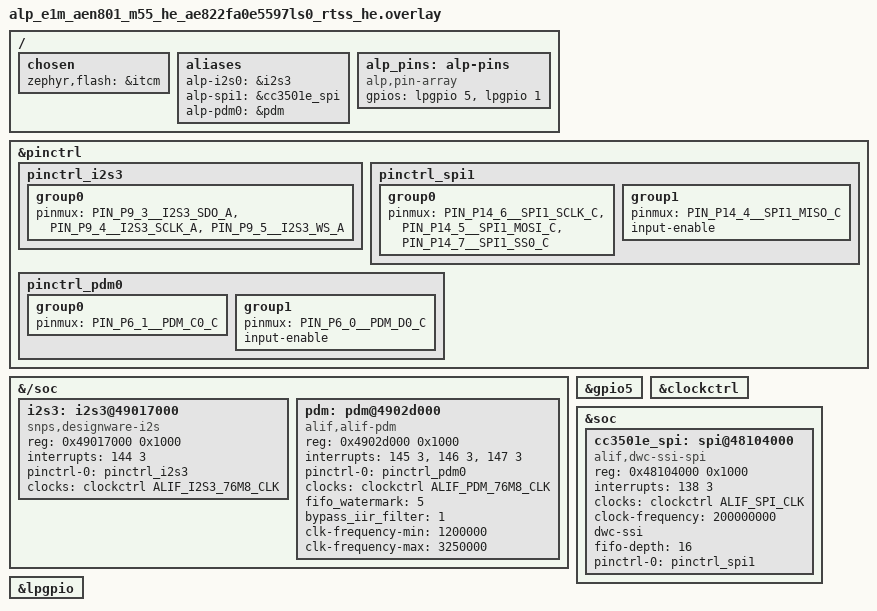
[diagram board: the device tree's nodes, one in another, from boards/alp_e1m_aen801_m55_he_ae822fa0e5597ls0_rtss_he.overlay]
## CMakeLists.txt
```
# SPDX-License-Identifier: Apache-2.0
cmake_minimum_required(VERSION 3.20)

# PROBE_UNDERRUN (#2149 bench verification) needs CONFIG_LOG on -- see
# underrun.conf's own header. OVERLAY_CONFIG has to be set BEFORE
# find_package(Zephyr...) below for Zephyr's own Kconfig merge to pick it
# up; every other PROBE_* mode leaves PROBE_UNDERRUN undefined, so this is a
# no-op for them.
if(DEFINED PROBE_UNDERRUN)
  list(APPEND OVERLAY_CONFIG "${CMAKE_CURRENT_SOURCE_DIR}/underrun.conf")
endif()

find_package(Zephyr REQUIRED HINTS $ENV{ZEPHYR_BASE})
project(aen_i2s_tas2563_probe LANGUAGES C)
target_sources(app PRIVATE src/main.c)

# BENCH-TEST (test/u46-i2s-tas2563-on-reworked-mux), not upstream: the
# CC3501E bridge bring-up helper + this app's two-entry GPIO-proxy route
# table, needed to drive the I2S0 mux SELECT + ENABLE (E1M IO13/IO8) before
# touching i2s3 on the reworked e1m-aen-evk-03 bench board -- see the board
# overlay and src/main.c.
target_sources(app PRIVATE src/cc3501e_bridge.c src/cc3501e_gpio_routes.c)

# PROBE_LISTEN (test/u46-i2s-tas2563-on-reworked-mux): compile-time switch to
# src/main.c's attended-listening variant (long continuous tone + a page-0
# register dump, no PASS/FAIL verdict) instead of the normal automated probe.
# Opt in with `west build ... -- -DPROBE_LISTEN=1`; unset (the default),
# this app is unchanged.
if(DEFINED PROBE_LISTEN)
  target_compile_definitions(app PRIVATE PROBE_LISTEN=${PROBE_LISTEN})
endif()

# PROBE_MELODY (test/u46-i2s-tas2563-on-reworked-mux): compile-time switch to
# src/main.c's short-tune variant (Ode to Joy, public domain) instead of the
# normal automated probe or PROBE_LISTEN's sustained tone. Opt in with
# `west build ... -- -DPROBE_MELODY=1`; unset (the default), this app is
# unchanged, same as PROBE_LISTEN unset.
if(DEFINED PROBE_MELODY)
  target_compile_definitions(app PRIVATE PROBE_MELODY=${PROBE_MELODY})
endif()

# PROBE_LOOPBACK (test/u46-i2s-tas2563-on-reworked-mux): compile-time switch
# to src/main.c's speaker-to-mic loopback variant (six tone/silence windows,
# integer-only per-sample stats + fixed-point Goertzel, a LIVE/DEAD/
# INCONCLUSIVE verdict) instead of the normal automated probe or the
# PROBE_LISTEN/PROBE_MELODY playback-only variants. Opt in with
# `west build ... -- -DPROBE_LOOPBACK=1`; unset (the default), this app is
# unchanged, same as PROBE_LISTEN/PROBE_MELODY unset.
if(DEFINED PROBE_LOOPBACK)
  target_compile_definitions(app PRIVATE PROBE_LOOPBACK=${PROBE_LOOPBACK})
endif()

# PROBE_RESUME (test/u46-i2s-tas2563-on-reworked-mux): compile-time switch to
# src/main.c's #2146 bench-verification variant (tas2563_resume() ordered
# start, a halt-time measurement, a restart-without-resume that reproduces
# the bug on purpose, a resume-after-restart that proves the fix, and a
# short-gap self-heal sweep) instead of the normal automated probe or the
# other three PROBE_* variants. Opt in with `west build ... --
# -DPROBE_RESUME=1`; unset (the default), this app is unchanged, same as
# the other three PROBE_* switches unset.
if(DEFINED PROBE_RESUME)
  target_compile_definitions(app PRIVATE PROBE_RESUME=${PROBE_RESUME})
endif()

# PROBE_RESUME2 (test/u46-i2s-tas2563-on-reworked-mux): compile-time switch
# to src/main.c's PROBE_RESUME + mic-measured-pitch variant -- the same A-F
# #2146 sequence, but with >=3 s of silence before every tone and an
# objective PDM-mic Goertzel pitch scan (200-4000 Hz) per tone/silence
# window, instead of trusting a listener's ear alone. Opt in with
# `west build ... -- -DPROBE_RESUME2=1`; unset (the default), this app is
# unchanged, same as the other four PROBE_* switches unset.
if(DEFINED PROBE_RESUME2)
  target_compile_definitions(app PRIVATE PROBE_RESUME2=${PROBE_RESUME2})
endif()

# PROBE_UNDERRUN (test/2149-underrun-bench): compile-time switch to
# src/main.c's #2149 speaker-safe silicon verification variant -- proves the
# DesignWare I2S bit clock keeps running across a TX underrun (never
# stopped by alp_audio_out_stop()) so the TAS2563 amps never see a clock-
# loss shutdown for an underrun, with a real stop()/start()-without-resume
# negative control (step 5) to prove the check itself can fail. Opt in with
# `west build ... -- -DPROBE_UNDERRUN=1`; unset (the default), this app is
# unchanged, same as every other PROBE_* switch unset. Also pulls in
# underrun.conf (see the OVERLAY_CONFIG block above) for CONFIG_LOG.
if(DEFINED PROBE_UNDERRUN)
  target_compile_definitions(app PRIVATE PROBE_UNDERRUN=${PROBE_UNDERRUN})
endif()
```

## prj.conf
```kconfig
# SPDX-License-Identifier: Apache-2.0
#
# aen-i2s-tas2563-probe -- bench RAM-run config for the E1M-AEN801 (M55-HE).
#
# BENCH-TEST (test/u46-i2s-tas2563-on-reworked-mux): proves the I2S0 path
# through the reworked U46 mux reaches the TAS2563 amps -- SEPARATE from
# test/2051-sdhc-enable-on-reworked-mux's SD test. See src/main.c and the
# board overlay for the full rationale.

CONFIG_ALP_SDK=y

# --- CC3501E bridge (drives the I2S0 mux SELECT + ENABLE) --------------------
# CONFIG_SPI/CONFIG_GPIO back the bridge (SPI1 + WIFI_EN/nRESET) and the GPIO
# proxy the mux drive needs -- both set explicitly because this app has no
# board.yaml `peripherals:` block to generate them (standalone Zephyr app,
# see CMakeLists.txt).
CONFIG_SPI=y
CONFIG_GPIO=y
CONFIG_ALP_SDK_CHIP_CC3501E=y
CONFIG_ALP_SDK_GPIO_CC3501E_PROXY=y

# --- I2S3 + TAS2563 x2 over I2C -----------------------------------------------
# CONFIG_ALP_SDK_AUDIO_OUT is `default y if I2S` (zephyr/kconfigs/
# iot-audio-inference.kconfig), so it comes on for free from CONFIG_I2S below
# -- alp_audio_out_open() (<alp/audio.h>) is what src/main.c uses to start
# I2S3 TX with volume control, the same lever examples/aen/aen-evk-demo's
# phase 11 uses to keep the amp quiet at first ACTIVE.
CONFIG_I2S=y
CONFIG_AUDIO=y
CONFIG_ALP_SDK_CHIP_TAS2563=y
CONFIG_I2C=y
CONFIG_PINCTRL=y

# --- PDM mics (the acoustic-loopback listener) --------------------------------
# CONFIG_ALP_SDK_AUDIO_IN is `default y if AUDIO_DMIC` (zephyr/kconfigs/
# iot-audio-inference.kconfig), so it comes on for free from CONFIG_AUDIO_DMIC
# below -- alp_audio_in_open() (<alp/audio.h>) is what src/main.c uses to
# capture from the pdm@4902d000 node the board overlay adds, the same
# portable capture surface examples/aen/aen-evk-demo's phase 11 uses for
# this exact mic pair. Real driver only, not the DMIC test-double behind
# CONFIG_ALP_SDK_AUDIO_SW_FALLBACK -- that one only auto-selects on
# native_sim.
CONFIG_AUDIO_DMIC=y

# The I2S TX slab (alp_i2s_open(), src/backends/i2s/zephyr_drv.c) is
# k_malloc'd -- a 2-block ping-pong slab at 256 stereo S16 frames/block is
# 2048 B total (256 frames x 2 channels x 2 bytes x 2 blocks). Headroom on
# top for the driver's own scratch. The audio_in (PDM) side is NOT heap in
# THIS backend -- its slab lives in a static per-handle pool
# (src/backends/audio/zephyr_drv.c's g_in_be_pool + hw_in_be.slab_buf[],
# confirmed by reading the struct -- a plain array, not a k_malloc), so it
# does not add to this budget by itself. Aligned to 16384 anyway, matching
# examples/aen/aen-pdm-mic-alif's bench-verified CONFIG_HEAP_MEM_POOL_SIZE
# (its own comment there claims the PCM path needs "a k_mem_slab + the
# kernel heap" -- that app's K_MEM_SLAB_DEFINE_STATIC is also a static
# array, not heap, so the exact mechanism that value covers is unclear from
# either app's own code; matching it costs nothing at our current headroom
# and removes heap size as a variable when comparing runs).
CONFIG_HEAP_MEM_POOL_SIZE=16384
# Bumped from 4096: the acoustic-loopback addition adds float locals
# (Goertzel state, composite dB tables) and a few hundred bytes of
# chan_result_t arrays on main()'s own frame -- the large buffers
# (tone_buf, mic_buf) stay static/BSS, not stack.
CONFIG_MAIN_STACK_SIZE=8192

# Float printf (%f/%e/%g) for the Goertzel tone-bin / RMS dB table below --
# picolibc's math functions (cosf/sqrtf/log10f) link without any extra
# Kconfig on this toolchain (same as examples/audio/butterworth-lowpass and
# several AI examples), but the *printf* float path is opt-in.
CONFIG_CBPRINTF_FP_SUPPORT=y

# FIFO is fed by the CPU from a plain buffer on BOTH audio peripherals here
# (i2s_dw and alif_pdm.c are both interrupt-driven, NOT DMA -- see
# src/main.c's file header) -- keep the data path coherent on this M55
# bench by disabling the D-cache, matching every other AEN801 bench app.
# Neither peripheral needs the sram0/DTCM-reachability workaround the SD
# test (test/2051-sdhc-enable-on-reworked-mux) needed for its ADMA
# descriptor table, for the same reason: no external bus master ever
# touches this app's audio buffers.
CONFIG_DCACHE=n

# --- Console -------------------------------------------------------------
# Alp UART console -- E1M edge UART0 (Alif UART5, P3_4/P3_5, 115200 8N1,
# NS16550), the E1M-AEN801 carrier console. The board _defconfig already
# selects it; we set it explicitly here so the example is self-describing.
CONFIG_SERIAL=y
CONFIG_CONSOLE=y
CONFIG_UART_CONSOLE=y
CONFIG_UART_INTERRUPT_DRIVEN=y
# Serial-less bench? Comment the four lines above and uncomment these to read
# 'ram_console_buf' over SWD instead:
# CONFIG_RAM_CONSOLE=y
# CONFIG_RAM_CONSOLE_BUFFER_SIZE=2048
# CONFIG_UART_CONSOLE=n
CONFIG_PRINTK=y
```

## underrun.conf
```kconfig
# SPDX-License-Identifier: Apache-2.0
#
# PROBE_UNDERRUN / PROBE_RX_TEARDOWN overlay (issues #2149 and #2171 bench
# verification). Pulled in by CMakeLists.txt ONLY when `-DPROBE_UNDERRUN=1`
# or `-DPROBE_RX_TEARDOWN=1` is set -- every other PROBE_* mode's build
# stays on the base prj.conf, which carries no CONFIG_LOG at all, so this
# file changes nothing for them.
#
# CONFIG_LOG_DEFAULT_LEVEL=2 (WRN) is the exact knob the alp_i2s_zephyr
# backend reads for its own compiled-in level -- src/backends/i2s/zephyr_drv.c:
# `LOG_MODULE_REGISTER(alp_i2s_zephyr, CONFIG_LOG_DEFAULT_LEVEL)` -- so this
# is what makes its `LOG_WRN_RATELIMIT("i2s: recovered from I2S_STATE_ERROR
# on write()", ...)` line actually reach the console during this bench run.
CONFIG_LOG=y
CONFIG_LOG_DEFAULT_LEVEL=2
```

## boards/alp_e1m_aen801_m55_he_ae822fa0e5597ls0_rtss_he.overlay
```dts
/*
 * Copyright (c) 2026 Alp Lab AB
 * SPDX-License-Identifier: Apache-2.0
 *
 * aen-i2s-tas2563-probe -- board overlay for the E1M-AEN801 (E8, M55-HE).
 *
 * ============================================================================
 * BENCH-TEST SCOPE -- READ THIS BEFORE REUSING THE OVERLAY ANYWHERE ELSE
 * ============================================================================
 * `i2s3` is ENABLED here, and the I2S0 mux SELECT + ENABLE are driven,
 * because the maintainer has PHYSICALLY REWORKED bench board
 * `e1m-aen-evk-03`: U46 (the I2S0 mux) plus U38/U39 were replaced with
 * 74LV3257 bus switches -- bidirectional, with a TRUE high-impedance state
 * when `/E` is deasserted -- in place of the stock 74LVC157, a unidirectional
 * logic mux whose SoC-facing Y outputs are forced LOW, never released,
 * whenever `/E` is HIGH. That forced-low, unidirectional behaviour is why
 * `i2s3` ships "disabled" in examples/aen/aen-i2s-amp-alif and
 * examples/aen/aen-evk-demo's board overlays (enabling it would fight the
 * SoC's own I2S3 TX pads through U46 the instant pinctrl is applied,
 * regardless of whether the mux ENABLE is ever asserted) -- and that
 * reasoning IS STILL CORRECT for every 2626-R2 carrier that has NOT had
 * this rework done, which is most of them.
 *
 * This overlay is a BENCH TEST for the one reworked board, not a rescoping
 * of #2077. Do NOT read this as "the mux defect is fixed, I2S playback is
 * safe to re-enable in general" -- that is a separate decision the
 * maintainer has not made. See src/main.c's file header for the same
 * caveat and the objective (no-ears-needed) pass/fail this app runs.
 * ============================================================================
 *
 * `i2s3@49017000` (TX-only pinctrl: SDO/SCLK/WS on P9_3/4/5) is transcribed
 * from examples/aen/aen-i2s-amp-alif's overlay -- see that file's header for
 * the "why i2s3, not i2s0" pinout derivation. The 76.8 MHz audio clock is
 * enabled by `clocks = <&clockctrl ALIF_I2S3_76M8_CLK>` plus the Tier-1.5
 * clockctrl west-patch (zephyr/patches/zephyr/
 * 0001-clock_control_alif-master-source-expmst-i2s-setrate.patch); no
 * app-level register poke is needed.
 *
 * `gpio5` -- EVK_PIN_AMP_ENABLE (SPI0_CS0 = P5_2, active-high SD_N) and
 * EVK_PIN_AMP_FAULT (SPI0_MISO = P5_0, open-drain IRQ_N) -- transcribed from
 * examples/aen/aen-evk-demo's overlay. Both are "overlay pins"
 * (metadata/boards/e1m-evk.yaml's overlay_pins: block) past the standard
 * 52-slot E1M map this standalone app does not carry, so src/main.c reaches
 * them via pinctrl_configure_pins() with a raw PIN_Pxx__GPIO mux, then the
 * standard Zephyr gpio_pin_* API against DEVICE_DT_GET(DT_NODELABEL(gpio5))
 * directly. This node only needs status = "okay"; gpio_dw applies no pad
 * mux of its own.
 *
 * The I2S0 mux SELECT (E1M IO13 -> CC3501E GPIO_13) and ENABLE (E1M IO8 ->
 * CC3501E GPIO_30) are NOT in this file -- like the SD mux ENABLE on
 * test/2051-sdhc-enable-on-reworked-mux, both are CC3501E-proxied pads
 * driven at runtime over the inter-chip bridge (src/cc3501e_gpio_routes.c).
 * Devicetree describes neither.
 *
 * The carrier I2C bus the TAS2563 amps sit on (ALP_E1M_I2C0 / portable
 * alp-i2c0, SoC I2C2) is a BOARD fact, already enabled at the board layer
 * for every AEN801/AEN803 app -- see examples/aen/aen-bmi323-regcheck's
 * overlay for the same argument made in full. Nothing to add here.
 *
 * ACOUSTIC LOOPBACK ADDITION (test/u46-i2s-tas2563-on-reworked-mux):
 * `pdm@4902d000` (the HP PDM, NOT `lppdm@43002000`) + its P6_1/P6_0 pinctrl
 * are transcribed from examples/aen/aen-pdm-mic-alif and
 * examples/aen/aen-evk-demo's overlays -- see either file's header for the
 * full from-alif.tsv derivation. Only the FIRST mic pair (U19 LEFT / U20
 * RIGHT, PDM_C0/D0) is declared: <alp/audio.h>'s Zephyr backend caps
 * channels at 2 (src/backends/audio/zephyr_drv.c), so the second pair
 * (U25/U26 on PDM_C1/D1) is unreachable through the portable capture API
 * regardless of whether its pads are declared here -- same reasoning
 * aen-evk-demo's phase 11 already used for this exact mic. NO MUX in this
 * path -- see src/main.c's file header for the netlist trace confirming
 * PDM_C0/D0 reach U19/U20 through nothing but series resistors (R69-R72),
 * unlike the I2S0/SDIO paths above.
 */

#include <zephyr/dt-bindings/pinctrl/alif-ensemble-pinctrl.h>
#include <zephyr/dt-bindings/clock/alif-ensemble-clocks-ext.h>
#include <zephyr/dt-bindings/gpio/gpio.h>

/ {
	chosen {
		zephyr,flash = &itcm; /* bench RAM/SES-load; path-ref form */
		/delete-property/ zephyr,code-partition;
	};
	aliases {
		alp-i2s0 = &i2s3;
	};
};

&pinctrl {
	pinctrl_i2s3: pinctrl_i2s3 {
		/* TX only: SDO + SCLK + WS. SDI (P9_2) is not declared -- this
		 * app never reads back over I2S. */
		group0 {
			pinmux = <PIN_P9_3__I2S3_SDO_A>, <PIN_P9_4__I2S3_SCLK_A>,
				 <PIN_P9_5__I2S3_WS_A>;
		};
	};
};

&{/soc} {
	i2s3: i2s3@49017000 {
		compatible = "snps,designware-i2s";
		reg = <0x49017000 0x1000>;
		interrupts = <144 3>;
		pinctrl-0 = <&pinctrl_i2s3>;
		pinctrl-names = "default";
		clocks = <&clockctrl ALIF_I2S3_76M8_CLK>;
		/* Enabled -- this app IS the bench test for the reworked U46.
		 * See the file header SAFETY note above. */
		status = "okay";
	};
};

/* AMP_ENABLE (P5_2) / AMP_FAULT (P5_0) -- see the file-header comment above. */
&gpio5 {
	status = "okay";
};

/*
 * ============================================================================
 * The SoM-internal Alif <-> CC3501E Wi-Fi/BLE bridge -- needed to DRIVE the
 * I2S0 mux SELECT + ENABLE, not to read the amps over I2C
 * ============================================================================
 * Ported verbatim from examples/aen/aen-cc3501e-gpio's overlay -- read that
 * file's header for the full derivation behind every value here (SPI1
 * pinctrl, the DWC_ssi SPI1 node, the LP-GPIO island).
 */

&pinctrl {
	/*
	 * SPI1 master on P14_6 (SCK) / P14_5 (MOSI) / P14_4 (MISO), plus the
	 * hardware SS0 chip-select on P14_7. SS0 is the dwc-ssi peripheral's
	 * OWN select -- not a GPIO bodge, not CS-less, not static-low: the
	 * master asserts/deasserts it per transfer, framing each phase of the
	 * bridge's request/reply exchange. Do NOT add cs-gpios here.
	 *
	 * input-enable on MISO because a pad's INPUT BUFFER is a PADCTRL bit
	 * that only pinctrl sets on this SoC -- without it the pad never
	 * senses what the slave drives.
	 */
	pinctrl_spi1: pinctrl_spi1 {
		group0 {
			pinmux = <PIN_P14_6__SPI1_SCLK_C>, <PIN_P14_5__SPI1_MOSI_C>,
				 <PIN_P14_7__SPI1_SS0_C>;
		};
		group1 {
			pinmux = <PIN_P14_4__SPI1_MISO_C>;
			input-enable;
		};
	};
};

/*
 * DWC_ssi SPI1 (AHB) -- the on-SoM CC3501E inter-chip link. Deliberately not
 * in ensemble_e8_peripherals.dtsi (which declares only the customer-facing
 * edge SPI0), so the consuming app declares it. reg 0x48104000 = the SPI1
 * base (+0x1000 per instance from spi0's 0x48103000). clock-frequency is
 * REQUIRED: without it spi_dw_alif's configure takes the clock-control path,
 * which fails -EINVAL for the gateless dummy ALIF_SPI_CLK. 200 MHz is the
 * real SSI functional clock (E8 HWRM); BAUDR = clock-frequency / freq_hz.
 */
&clockctrl {
	status = "okay";
};

&soc {
	cc3501e_spi: spi@48104000 {
		compatible = "alif,dwc-ssi-spi";
		#address-cells = <1>;
		#size-cells = <0>;
		reg = <0x48104000 0x1000>;
		interrupts = <138 3>;          /* BENCH-TBD: confirm SPI1 IRQ */
		clocks = <&clockctrl ALIF_SPI_CLK>;
		clock-frequency = <200000000>;
		dwc-ssi;
		fifo-depth = <16>;
		pinctrl-0 = <&pinctrl_spi1>;
		pinctrl-names = "default";
		status = "okay";
	};
};

/*
 * Enable the LP GPIO island so WIFI_EN (P15_5) and E_WIFI.NRST (P15_1_FLEX)
 * are drivable as outputs. P15_1/P15_5 function 0 (the reset default) IS
 * LPGPIO, so no pinctrl group is needed for their mux.
 */
&lpgpio {
	status = "okay";
};

/ {
	aliases {
		/* bus_id 1 in alp_spi_open() -> this controller. */
		alp-spi1 = &cc3501e_spi;
	};

	/*
	 * Compact 2-entry control array for the SoM-internal CC3501E nets, in
	 * the order cc3501e_bridge.h's CC3501E_BRIDGE_PIN_* indices expect.
	 * These are NOT E1M edge pads, so this app does not use the 52-slot
	 * positional E1M map. There must be exactly ONE "alp,pin-array" node
	 * in the tree.
	 */
	alp_pins: alp-pins {
		compatible = "alp,pin-array";
		gpios = <&lpgpio 5 GPIO_ACTIVE_HIGH>,   /* [0] WIFI_EN     (P15_5)      */
			<&lpgpio 1 GPIO_ACTIVE_HIGH>;   /* [1] E_WIFI.NRST (P15_1_FLEX) */
	};
};

/*
 * ============================================================================
 * On-board PDM mics (the acoustic loopback listener) -- see the file-header
 * ACOUSTIC LOOPBACK ADDITION note above
 * ============================================================================
 */

&pinctrl {
	pinctrl_pdm0: pinctrl_pdm0 {
		/* Clock (output) -- no input-enable needed. C0 = P6_1. */
		group0 {
			pinmux = <PIN_P6_1__PDM_C0_C>;
		};
		/* Data (input) -- input-enable sets the pad REN, same trap called
		 * out for the SPI1 MISO group above. D0 = P6_0. */
		group1 {
			pinmux = <PIN_P6_0__PDM_D0_C>;
			input-enable;
		};
	};
};

&{/soc} {
	pdm: pdm@4902d000 {
		compatible = "alif,alif-pdm";
		reg = <0x4902d000 0x1000>;
		interrupts = <145 3>, <146 3>, <147 3>;
		interrupt-names = "warning_intr", "error_intr", "audio_det_intr";
		pinctrl-0 = <&pinctrl_pdm0>;
		pinctrl-names = "default";
		clocks = <&clockctrl ALIF_PDM_76M8_CLK>;
		fifo_watermark = <5>;
		bypass_iir_filter = <1>;
		status = "okay";

		/*
		 * #2133 ROUND 3: U19/U20 are ST MP34DT05TR-A parts; ST's own
		 * Zephyr driver for this family (zephyr/drivers/audio/
		 * mpxxdtyy.h:19-20) states a 1.2-3.25 MHz PDM bit-clock spec
		 * (MPXXDTYY_MIN_PDM_FREQ / MPXXDTYY_MAX_PDM_FREQ) -- BOTH the
		 * 8 kHz mode (512 kHz clock) and the 16 kHz mode (1024 kHz
		 * clock) this board's PDM controller can generate are below
		 * that floor and were never in spec for this mic. 48 kHz
		 * (mode 7, 3072 kHz clock) is in spec. These properties (now
		 * declared by alif,alif-pdm.yaml) make dmic_alif_pdm_configure()
		 * reject any clock mode outside this board's mic range instead
		 * of silently under-clocking the mics -- see src/main.c's file
		 * header "MIC CAPTURE RATE IS 48 kHz" section for the full
		 * derivation.
		 */
		clk-frequency-min = <1200000>; /* mpxxdtyy.h MPXXDTYY_MIN_PDM_FREQ */
		clk-frequency-max = <3250000>; /* mpxxdtyy.h MPXXDTYY_MAX_PDM_FREQ */
	};
};

/ {
	aliases {
		alp-pdm0 = &pdm;
	};
};
```

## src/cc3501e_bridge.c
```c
/*
 * SPDX-License-Identifier: Apache-2.0
 * Copyright 2026 Alp Lab AB
 *
 * E1M-AEN SoM CC3501E bridge bring-up helper -- copied verbatim from
 * examples/aen/aen-cc3501e-gpio/src/cc3501e_bridge.c. See cc3501e_bridge.h.
 */

#include "cc3501e_bridge.h"

#if defined(CONFIG_BOARD_ALP_E1M_AEN801_M55_HE)
#include <zephyr/arch/cpu.h>
#include <zephyr/sys/sys_io.h>
/*
 * AEN LP-pad mux (Alif Ensemble E8, M55-HE). WIFI_EN (P15_5) and nRESET
 * (P15_1) are on the Alif LP-GPIO island, bound by the generic
 * snps,designware-gpio driver which does NOT apply Alif pinctrl -- so the LP
 * pads stay un-muxed and their output drivers OFF unless poked directly.
 * 0x23 = the Alif GPIO-output pad config (driver + read-enable + drive
 * strength).
 */
#define ALIF_LPGPIO_PADCTRL_BASE 0x42007000u
#define ALIF_PAD_GPIO_OUTPUT     0x23u
static void aen_lp_pads_enable_output(void)
{
	sys_write32(ALIF_PAD_GPIO_OUTPUT, ALIF_LPGPIO_PADCTRL_BASE + 5u * 4u); /* P15_5 WIFI_EN */
	sys_write32(ALIF_PAD_GPIO_OUTPUT, ALIF_LPGPIO_PADCTRL_BASE + 1u * 4u); /* P15_1 nRESET  */
}
#else
static inline void aen_lp_pads_enable_output(void)
{
}
#endif

alp_status_t cc3501e_bridge_bringup(cc3501e_t *fw)
{
	if (fw == NULL) {
		return ALP_ERR_INVAL;
	}

	/* 1. Control pins: WIFI_EN (supply gate) + nRESET. These are Alif
	 *    LP-GPIO pads, not E1M edge pads -- the SoM owns them. */
	alp_gpio_t *wifi_en = alp_gpio_open(CC3501E_BRIDGE_PIN_WIFI_EN);
	alp_gpio_t *nrst    = alp_gpio_open(CC3501E_BRIDGE_PIN_NRST);
	if (wifi_en == NULL || nrst == NULL) {
		if (wifi_en != NULL) {
			alp_gpio_close(wifi_en);
		}
		if (nrst != NULL) {
			alp_gpio_close(nrst);
		}
		return ALP_ERR_NOT_PRESENT_ON_THIS_SOC;
	}
	aen_lp_pads_enable_output();
	(void)alp_gpio_configure(wifi_en, ALP_GPIO_OUTPUT, ALP_GPIO_PULL_NONE);
	(void)alp_gpio_configure(nrst, ALP_GPIO_OUTPUT, ALP_GPIO_PULL_NONE);

	/* 2. Inter-chip SPI (Alif = master). CS is the dwc-ssi hardware SS0
	 *    muxed on P14_7; the app passes ALP_SPI_NO_CS so no software GPIO
	 *    CS is installed and the SPI controller drives SS0 per transfer.
	 *    Mode 0 matches the CC3501E vendor image frameFormat. */
	alp_spi_t *spi = alp_spi_open(&(alp_spi_config_t){
	    .bus_id        = CC3501E_BRIDGE_SPI_BUS_ID,
	    .freq_hz       = CC3501E_BRIDGE_SPI_FREQ_HZ,
	    .mode          = ALP_SPI_MODE_0,
	    .bits_per_word = 8u,
	    .cs_pin_id     = ALP_SPI_NO_CS,
	});
	if (spi == NULL) {
		alp_gpio_close(wifi_en);
		alp_gpio_close(nrst);
		return ALP_ERR_NOT_PRESENT_ON_THIS_SOC;
	}

#if CC3501E_BRIDGE_RX_SAMPLE_DLY > 0
	/* Raise the SCLK past 1 MHz -- see cc3501e_bridge.h for the derivation. */
	{
		volatile uint32_t *ssienr =
		    (volatile uint32_t *)(uintptr_t)(CC3501E_BRIDGE_SPI1_BASE + 0x08u);
		volatile uint32_t *rsd = (volatile uint32_t *)(uintptr_t)(CC3501E_BRIDGE_SPI1_BASE + 0xf0u);
		uint32_t           en  = *ssienr;
		*ssienr                = 0u;
		*rsd                   = (uint32_t)CC3501E_BRIDGE_RX_SAMPLE_DLY;
		*ssienr                = en;
	}
#endif

	/* 3. Bind the bus + control pins; attach the GPIO proxy (proxied E1M
	 *    IOs then route over the bridge); run the power + reset sequence.
	 *    Leaves WIFI_EN HIGH. */
	(void)cc3501e_init(fw, spi);
	fw->enable_pin = wifi_en;
	fw->reset_pin  = nrst;
	/* Optional host-IRQ/READY line -- not wired by this app's overlay
	 * (2-entry alp_pins array), so this returns NULL and the driver keeps
	 * the fixed-gap fallback. */
	alp_gpio_t *ready = alp_gpio_open(CC3501E_BRIDGE_PIN_READY);
	if (ready != NULL) {
		(void)alp_gpio_configure(ready, ALP_GPIO_INPUT, ALP_GPIO_PULL_NONE);
		fw->ready_pin = ready;
	}
#ifdef CONFIG_ALP_SDK_GPIO_CC3501E_PROXY
	(void)alp_gpio_cc3501e_attach(fw);
#endif
#ifdef CONFIG_ALP_SDK_WIFI_CC3501E
	(void)alp_wifi_cc3501e_attach(fw);
#endif
#ifdef CONFIG_ALP_SDK_BLE_CC3501E
	(void)alp_ble_cc3501e_attach(fw);
#endif
	return cc3501e_reset(fw);
}
```

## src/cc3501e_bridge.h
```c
/*
 * SPDX-License-Identifier: Apache-2.0
 * Copyright 2026 Alp Lab AB
 *
 * One-call bring-up of the E1M-AEN SoM's CC3501E Wi-Fi 6 / BLE coprocessor
 * over the inter-chip SPI bridge -- copied verbatim from
 * examples/aen/aen-cc3501e-gpio/src/cc3501e_bridge.h.
 *
 * BENCH-TEST SCOPE: this app needs the bridge for exactly ONE reason -- to
 * drive the I2S0 mux SELECT + ENABLE (E1M IO13 -> CC3501E GPIO_13, E1M IO8
 * -> CC3501E GPIO_30) before touching i2s3, on the physically reworked
 * e1m-aen-evk-03 bench board (U46 74LVC157 -> 74LV3257). See the board
 * overlay and src/main.c for the full rationale; this file itself is
 * unmodified SoM bring-up boilerplate, not a mux-specific detail.
 *
 * The CC3501E is part of the SoM (module U4 = BDE-BW35N): the application
 * does NOT touch the raw SPI bus or the WIFI_EN / nRESET control pins. It
 * calls cc3501e_bridge_bringup() once, gets a ready @ref cc3501e_t, and from
 * there uses the portable surfaces:
 *   - cc3501e_* (chips/cc3501e)            -- MAC / Wi-Fi / BLE / GPIO-proxy / OTA
 *   - alp_gpio_open(ALP_E1M_GPIO_IOxx)         -- proxied E1M IOs (when the proxy is built)
 */

#ifndef CC3501E_BRIDGE_H
#define CC3501E_BRIDGE_H

#include <alp/peripheral.h>    /* alp_status_t */
#include <alp/chips/cc3501e.h> /* cc3501e_t */

/* ---- E1M-AEN SoM bridge defaults (override per board variant) ---------------- */

#ifndef CC3501E_BRIDGE_SPI_BUS_ID
#define CC3501E_BRIDGE_SPI_BUS_ID 1u
#endif
#ifndef CC3501E_BRIDGE_SPI_FREQ_HZ
/* 25 MHz = 200 MHz SSI functional clock / 8 -- see
 * examples/aen/aen-cc3501e-gpio/src/cc3501e_bridge.h for the full derivation
 * (silicon-measured on E1M-AEN803 serial 2026W36-0002). */
#define CC3501E_BRIDGE_SPI_FREQ_HZ 25000000u
#endif

/* CC3501E control pins on the Alif LP-GPIO island (NOT E1M edge pads):
 * WIFI_EN = supply gate (P15_5), nRESET = reset (P15_1_FLEX). */
#ifndef CC3501E_BRIDGE_PIN_WIFI_EN
#define CC3501E_BRIDGE_PIN_WIFI_EN 0u
#endif
#ifndef CC3501E_BRIDGE_PIN_NRST
#define CC3501E_BRIDGE_PIN_NRST 1u
#endif
/* OPTIONAL host-IRQ/READY input -- not wired by this app's overlay (2-entry
 * alp_pins array), so alp_gpio_open() on this index returns NULL and
 * cc3501e_request() falls back to its fixed-gap delay. */
#ifndef CC3501E_BRIDGE_PIN_READY
#define CC3501E_BRIDGE_PIN_READY 2u
#endif

/* DW SSI SPI1 base (0x48104000) + RX_SAMPLE_DLY to run the bridge SCLK above
 * 1 MHz. 4 is silicon-measured at the 25 MHz working point -- see
 * examples/aen/aen-cc3501e-gpio/src/cc3501e_bridge.h for the sweep data. */
#ifndef CC3501E_BRIDGE_SPI1_BASE
#define CC3501E_BRIDGE_SPI1_BASE 0x48104000u
#endif
#ifndef CC3501E_BRIDGE_RX_SAMPLE_DLY
#define CC3501E_BRIDGE_RX_SAMPLE_DLY 4u
#endif

/**
 * @brief Bring up the SoM's CC3501E coprocessor over the inter-chip bridge.
 *
 * Opens the hardware-SS0 bridge SPI + the WIFI_EN / nRESET control pins,
 * binds them to @p fw, attaches the GPIO proxy (when
 * CONFIG_ALP_SDK_GPIO_CC3501E_PROXY is built), and runs the power + reset
 * sequence. Blocks ~900 ms for the boot budget; leaves WIFI_EN HIGH.
 *
 * @param fw  Caller-owned handle, populated on success. Use it with cc3501e_*.
 * @return ALP_OK with @p fw ready; ALP_ERR_NOT_PRESENT_ON_THIS_SOC if the SPI
 *         bus / control pins are absent (check the board overlay); otherwise
 *         the reset sequence status. On any failure @p fw is left un-bound.
 */
alp_status_t cc3501e_bridge_bringup(cc3501e_t *fw);

#endif /* CC3501E_BRIDGE_H */
```

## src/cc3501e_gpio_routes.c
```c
/*
 * SPDX-License-Identifier: Apache-2.0
 * Copyright 2026 Alp Lab AB
 *
 * Strong override of the WEAK cc3501e_gpio_routes[] / cc3501e_gpio_route_count
 * in src/backends/gpio/cc3501e_proxy_routes_weak.c (empty by default). This
 * app needs exactly TWO proxied pins -- the I2S0 mux SELECT and ENABLE -- so
 * it carries two entries rather than the full generated table
 * (examples/aen/aen-cc3501e-gpio/src/cc3501e_gpio_routes.c and siblings) --
 * see that file's own header for the generator + the other AEN801 routes.
 *
 * ALP_E1M_GPIO_IO13 -> raw CC3501E GPIO_13 -- the I2S0 74LVC157 (now 74LV3257
 * on the reworked bench board) mux SELECT; 0 = TAS2563 amps.
 * ALP_E1M_GPIO_IO8  -> raw CC3501E GPIO_30 -- the same mux's ENABLE, active
 * low.
 * metadata/e1m_modules/E1M-AEN801.yaml:336-345.
 */

#include <stddef.h>

#include <alp/chips/cc3501e.h>
#include <alp/e1m_pinout.h>

const cc3501e_gpio_route_t cc3501e_gpio_routes[] = {
	{ ALP_E1M_GPIO_IO13, 13u }, /* I2S0 mux SELECT; drive low to pick the amps. */
	{ ALP_E1M_GPIO_IO8, 30u },  /* I2S0 mux /E; drive low to enable mux. */
};

const size_t cc3501e_gpio_route_count =
    sizeof(cc3501e_gpio_routes) / sizeof(cc3501e_gpio_routes[0]);
```
